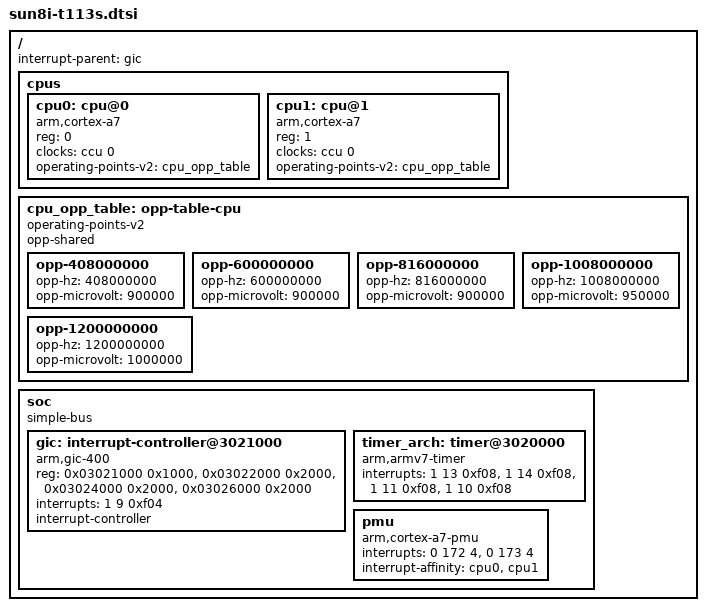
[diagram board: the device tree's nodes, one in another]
// SPDX-License-Identifier: (GPL-2.0+ OR MIT)
/* 纯数字硬编码版 - CPU定义 */

/ {
	#address-cells = <1>;
	#size-cells = <1>;
	interrupt-parent = <&gic>;

	cpus {
		#address-cells = <1>;
		#size-cells = <0>;

		cpu0: cpu@0 {
			compatible = "arm,cortex-a7";
			device_type = "cpu";
			reg = <0>;
			clocks = <&ccu 0>; /* CLK_CPUX = 0 */
			clock-names = "cpu";
			operating-points-v2 = <&cpu_opp_table>;
		};

		cpu1: cpu@1 {
			compatible = "arm,cortex-a7";
			device_type = "cpu";
			reg = <1>;
			clocks = <&ccu 0>;
			clock-names = "cpu";
			operating-points-v2 = <&cpu_opp_table>;
		};
	};

	cpu_opp_table: opp-table-cpu {
		compatible = "operating-points-v2";
		opp-shared;

		opp-408000000 {
			opp-hz = /bits/ 64 <408000000>;
			opp-microvolt = <900000>;
		};

		opp-600000000 {
			opp-hz = /bits/ 64 <600000000>;
			opp-microvolt = <900000>;
		};

		opp-816000000 {
			opp-hz = /bits/ 64 <816000000>;
			opp-microvolt = <900000>;
		};

		opp-1008000000 {
			opp-hz = /bits/ 64 <1008000000>;
			opp-microvolt = <950000>;
		};

		opp-1200000000 {
			opp-hz = /bits/ 64 <1200000000>;
			opp-microvolt = <1000000>;
		};
	};

	soc {
		compatible = "simple-bus";
		#address-cells = <1>;
		#size-cells = <1>;
		ranges;

		gic: interrupt-controller@3021000 {
			compatible = "arm,gic-400";
			reg = <0x03021000 0x1000>,
			      <0x03022000 0x2000>,
			      <0x03024000 0x2000>,
			      <0x03026000 0x2000>;
			/* GIC_PPI=1, IRQ_TYPE_LEVEL_HIGH=4 */
			interrupts = <1 9 0xf04>;
			interrupt-controller;
			#interrupt-cells = <3>;
		};

		timer_arch: timer@3020000 {
			compatible = "arm,armv7-timer";
			interrupts = <1 13 0xf08>,
				     <1 14 0xf08>,
				     <1 11 0xf08>,
				     <1 10 0xf08>;
		};

		pmu {
			compatible = "arm,cortex-a7-pmu";
			/* GIC_SPI=0, 172/173, IRQ_TYPE_LEVEL_HIGH=4 */
			interrupts = <0 172 4>, <0 173 4>;
			interrupt-affinity = <&cpu0>, <&cpu1>;
		};
	};
};

#include "sun20i-d1s.dtsi"
